# STM32MP21_CA35 register map
File version: 0.4
CPU: CM33 r0p1, little endian, MPU, FPU, vendor SysTick, 8 interrupt priority bits
Registers are 32-bit, read-write, reset 0x0 unless marked. A register's access mark holds for its fields unless they carry their own. Offsets are from the block's base; [hi:lo] are bit positions; {n}, {i} and the like mark numbered series.

## SAES — SAES register block
Base 0x42030C00
Same registers: SAES_S 0x52030C00
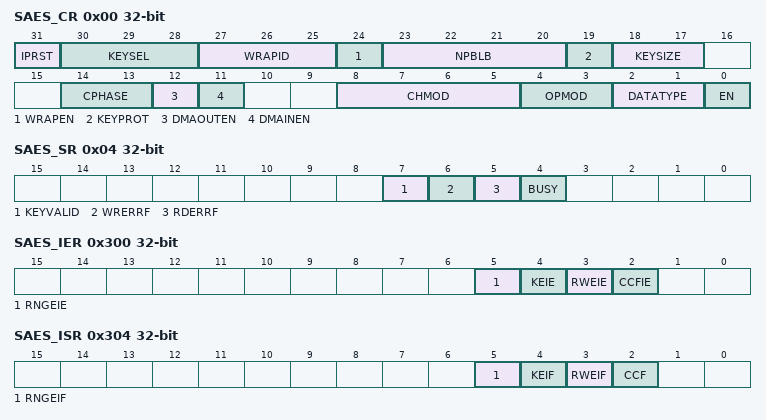
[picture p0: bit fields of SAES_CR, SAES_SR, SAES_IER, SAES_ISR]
0x00 SAES_CR — SAES control register
  [31] IPRST — SAES peripheral software reset
  [30:28] KEYSEL — Key selection
    0=Software key, loaded in key registers SAES_KEYx; 1=Derived hardware unique key (DHUK); 2=Boot hardware key (BHK); 4=XOR of DHUK and BHK
  [27:25] WRAPID
    0=The SAES itself; 1=The CRYP1 peripheral, through key bus; 2=The CRYP2 peripheral, through key bus
  [24] WRAPEN — Wrap enable
    0=Normal key; 1=Wrapped key
  [23:20] NPBLB — Number of padding bytes in last block
    0=All bytes are valid (no padding); 1=Padding for the last LSB byte; 15=Padding for the 15 LSB bytes of last block
  [19] KEYPROT — Key protection
    0=When KEYVALID is set and KEYSEL[2:0]=0 application can transfer the ownership of the SAES, with its loaded key, to an application running in another security context (such as nonsecure, secure, specific CPU); 1=When KEYVALID is set, key error flag (KEIF) is set when an access to any registers is detected, this access having a security context (for example, secure, nonsecure, Compartment ID) that does not match the one of the application that loaded the key
  [18:17] KEYSIZE
    0=128-bit; 1=192-bit; 2=256-bit
  [14:13] CPHASE — Chaining phase
    0=Initialization phase; 1=Header phase; 2=Payload phase; 3=Final phase
  [12] DMAOUTEN — DMA output enable
    0=Disable; 1=Enable
  [11] DMAINEN — DMA input enable
    0=Disable; 1=Enable
  [8:5] CHMOD — Chaining mode
    0=Electronic codebook (ECB); 1=Cipher-Block Chaining (CBC); 2=Counter Mode (CTR); 3=Galois Counter Mode (GCM) and Galois Message Authentication Code (GMAC); 4=Counter with CBC-MAC (CCM)
  [4:3] OPMOD — Operating mode
    0=Encryption; 1=Key derivation (or key preparation), for ECB/CBC decryption only; 2=Decryption
  [2:1] DATATYPE
    0=No swapping (32-bit data); 1=Half-word swapping (16-bit data); 2=Byte swapping (8-bit data); 3=Bit-level swapping
  [0] EN — Enable
    0=Disable; 1=Enable
0x04 SAES_SR ro — SAES status register
  [7] KEYVALID — Key valid flag
    0=Key not valid; 1=Key valid
  [6] WRERRF — Write error flag
    0=No error; 1=Unexpected write to SAES_DINR register occurred during computation or data output phase
  [5] RDERRF — Read error flag
    0=No error; 1=Unexpected read to SAES_DOUTR register occurred during computation or data input phase
  [4] BUSY
    0=Idle; 1=Busy
0x08 SAES_DINR wo — SAES data input register
  [31:0] DIN — Data input
0x0C SAES_DOUTR ro — SAES data output register
  [31:0] DOUT — Data output
{0x20+4i} SAES_KEYR{i} wo (i=0..7) — SAES key register {i}
  [31:0] KEY — Cryptographic key, bits [{32i+31}:{32i}]
{0x40+4i} SAES_IVR{i} (i=0..3) — SAES initialization vector register {i}
  [31:0] IVI — Initialization vector input, bits [{32i+31}:{32i}]
{0x50+4i} SAES_CSR{i} (i=0..7) — SAES context swap registers
  [31:0] CS{i} — Context swap data x
0x300 SAES_IER — SAES interrupt enable register
  [all] fields
    0=Disabled (masked); 1=Enabled (not masked)
  [5] RNGEIE — RNG error interrupt enable
  [4] KEIE — Key error interrupt enable
  [3] RWEIE — Read or write error interrupt enable
  [2] CCFIE — Computation complete flag interrupt enable
0x304 SAES_ISR ro — SAES interrupt status register
  [5] RNGEIF — RNG error interrupt flag
    0=RNG bus is functional; 1=Error detected on RNG bus interface (random seed fetching error)
  [4] KEIF — Key error interrupt flag
    0=No key error detected; 1=Key information failed to load into key registers or the key register use is forbidden
  [3] RWEIF — Read or write error interrupt flag
    0=No read or write error detected; 1=Read or write error detected
  [2] CCF — Computation complete flag
    0=Not complete; 1=Complete
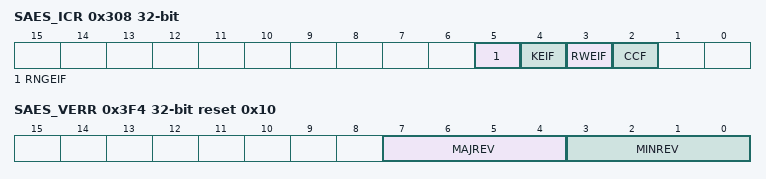
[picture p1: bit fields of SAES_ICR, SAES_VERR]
0x308 SAES_ICR wo — SAES interrupt clear register
  [5] RNGEIF — RNG error interrupt flag clear
  [4] KEIF — Key error interrupt flag clear
  [3] RWEIF — Read or write error interrupt flag clear
  [2] CCF — Computation complete flag clear
0x3F0 SAES_HWCFGR ro reset 0x1 — SAES hardware configuration register
  [3:0] CFG1 — HW Generic 1
0x3F4 SAES_VERR ro reset 0x10 — SAES version register
  [7:4] MAJREV — Major revision
  [3:0] MINREV — Minor revision
0x3F8 SAES_IPIDR ro reset 0x170012 — SAES identification register
  [31:0] ID — Identification code of the peripheral
0x3FC SAES_SIDR ro reset 0xA3C5DD01 — SAES size ID register
  [31:0] SID — Size identification code
